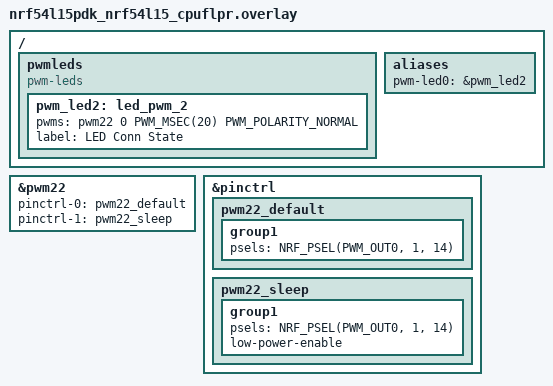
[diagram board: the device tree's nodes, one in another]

/ {
	pwmleds {
		compatible = "pwm-leds";
		status = "okay";

		pwm_led2: led_pwm_2 {
			status = "okay";
			pwms = <&pwm22 0 PWM_MSEC(20) PWM_POLARITY_NORMAL>;
			label = "LED Conn State";
		};
	};

	aliases {
		pwm-led0 = &pwm_led2;
	};
};

&pwm22 {
	status = "okay";
	pinctrl-0 = <&pwm22_default>;
	pinctrl-1 = <&pwm22_sleep>;
	pinctrl-names = "default", "sleep";
};

&pinctrl {
	pwm22_default: pwm22_default {
		group1 {
			psels = <NRF_PSEL(PWM_OUT0, 1, 14)>;
		};
	};

	pwm22_sleep: pwm22_sleep {
		group1 {
			psels = <NRF_PSEL(PWM_OUT0, 1, 14)>;
			low-power-enable;
		};
	};
};

